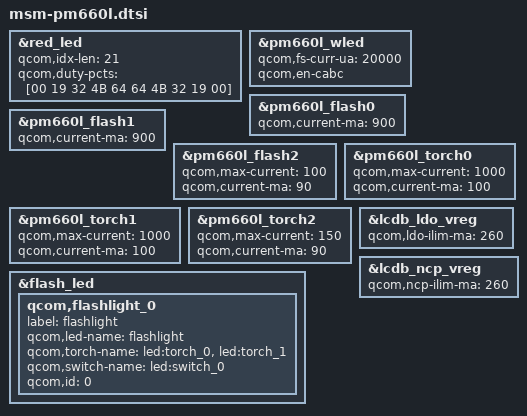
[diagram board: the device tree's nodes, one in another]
/* Copyright (c) 2016-2017, The Linux Foundation. All rights reserved.
 * Copyright (C) 2019 XiaoMi, Inc.
 *
 * This program is free software; you can redistribute it and/or modify
 * it under the terms of the GNU General Public License version 2 and
 * only version 2 as published by the Free Software Foundation.
 *
 * This program is distributed in the hope that it will be useful,
 * but WITHOUT ANY WARRANTY; without even the implied warranty of
 * MERCHANTABILITY or FITNESS FOR A PARTICULAR PURPOSE.  See the
 * GNU General Public License for more details.
 */

&red_led {
	qcom,idx-len = <21>;		// FIXME: bug in Xiaomi source, should be 10?
	qcom,duty-pcts = [00 19 32 4B 64 64 4B 32 19 00];
};

&pm660l_wled {
	qcom,fs-curr-ua = <20000>;
	qcom,en-cabc;
	/delete-property/ qcom,auto-calibration-enable;
};

&pm660l_flash0 {
	qcom,current-ma = <900>;
};

&pm660l_flash1 {
	qcom,current-ma = <900>;
};

&pm660l_flash2 {
	qcom,max-current = <100>;
	qcom,current-ma = <90>;
};

&pm660l_torch0 {
	qcom,max-current = <1000>;
	qcom,current-ma = <100>;
};

&pm660l_torch1 {
	qcom,max-current = <1000>;
	qcom,current-ma = <100>;
};

&pm660l_torch2 {
	qcom,max-current = <150>;
	qcom,current-ma = <90>;
};

&flash_led {
	qcom,flashlight_0 {
		label = "flashlight";
		qcom,led-name = "flashlight";
		qcom,torch-name = "led:torch_0", "led:torch_1";
		qcom,switch-name = "led:switch_0";
		qcom,id = <0>;
	};
};

&lcdb_ldo_vreg {
	qcom,ldo-ilim-ma = <260>;
};

&lcdb_ncp_vreg {
	qcom,ncp-ilim-ma = <260>;
};
